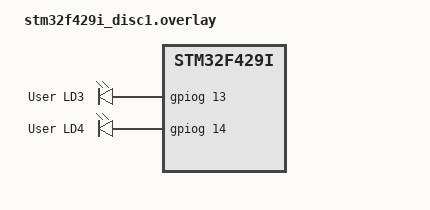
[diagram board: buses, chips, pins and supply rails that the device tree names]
/ {
    leds {
		compatible = "gpio-leds";

		green_led_3: led_3 {
			gpios = <&gpiog 13 GPIO_ACTIVE_HIGH>;
			label = "User LD3";
		};

		red_led_4: led_4 {
			gpios = <&gpiog 14 GPIO_ACTIVE_HIGH>;
			label = "User LD4";
		};
	};

    aliases {
		led0 = &green_led_3;
		led1 = &red_led_4;
	};
};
